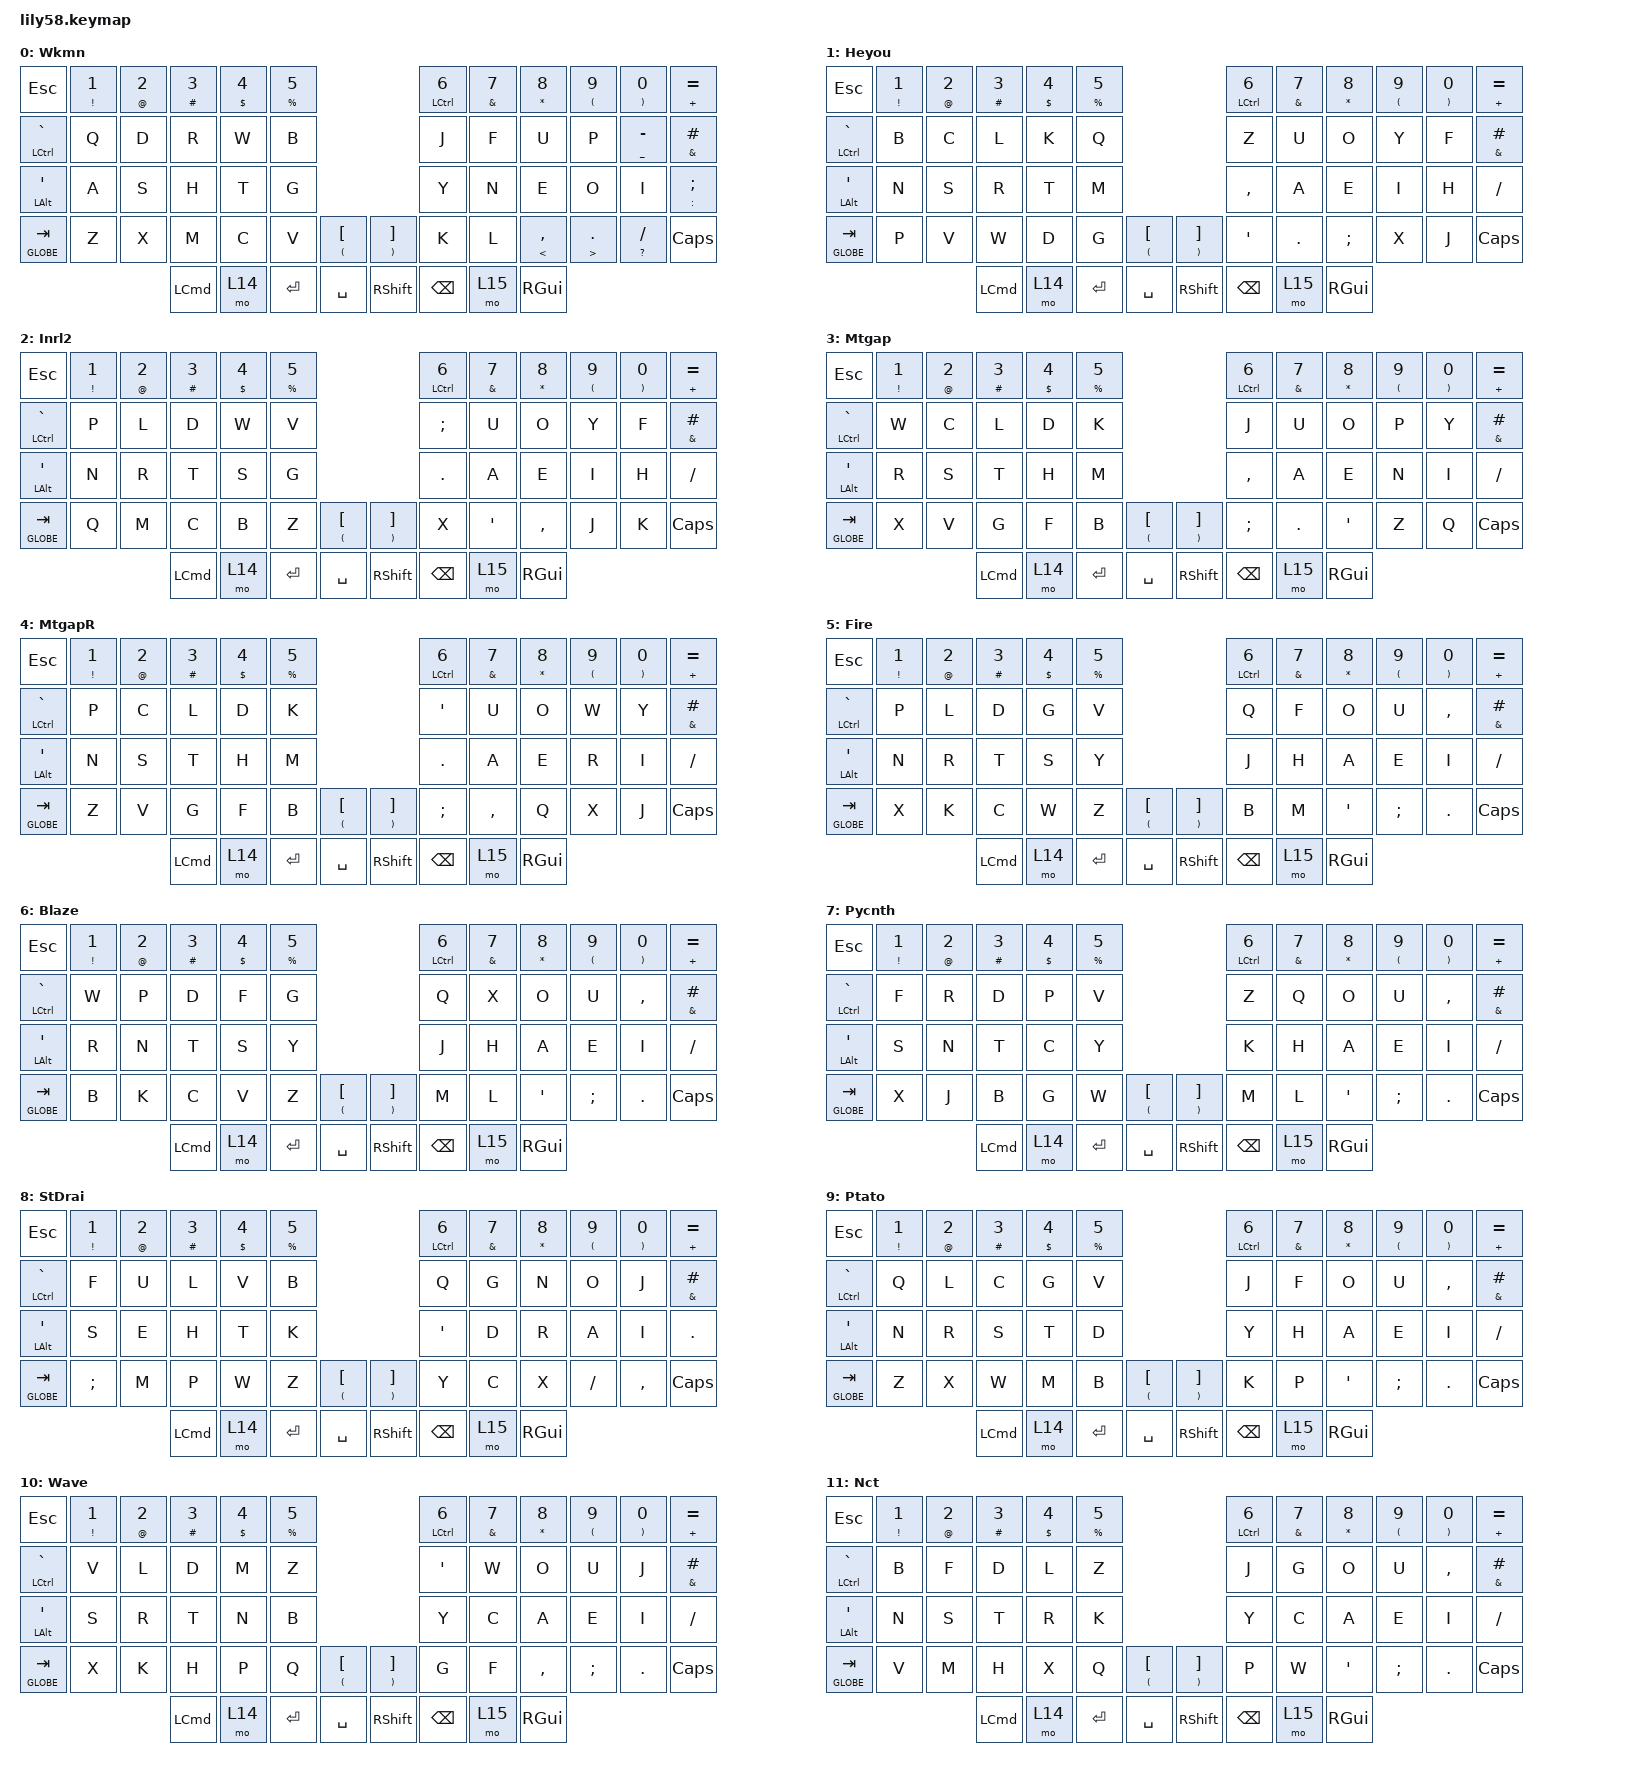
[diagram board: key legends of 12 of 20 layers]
/*
 * Copyright (c) 2020 The ZMK Contributors
 *
 * SPDX-License-Identifier: MIT
 */

#include <behaviors.dtsi>
#include <dt-bindings/zmk/keys.h>
#include <dt-bindings/zmk/pointing.h>

/ {
    combos { compatible = "zmk,combos"; };

    keymap {
        compatible = "zmk,keymap";

        Workman {
            // ------------------------------------------------------------------------------------------------------------
            // |  ESC  |  1  |  2  |  3   |  4   |  5   |                   |  6   |  7    |  8    |  9   |   0   |   `   |
            // |  TAB  |  Q  |  W  |  E   |  R   |  T   |                   |  Y   |  U    |  I    |  O   |   P   |   -   |
            // |  CTRL |  A  |  S  |  D   |  F   |  G   |                   |  H   |  J    |  K    |  L   |   ;   |   '   |
            // | SHIFT |  Z  |  X  |  C   |  V   |  B   |   "["  |  |  "]"  |  N   |  M    |  ,    |  .   |   /   | SHIFT |
            //                     | ALT  | GUI  | LOWER|  SPACE |  | ENTER | RAISE| BSPC  | GUI   |

            display-name = "Wkmn";
            bindings = <
&kp ESC                 &mt EXCLAMATION NUMBER_1  &mt AT_SIGN NUMBER_2  &mt HASH NUMBER_3  &mt DOLLAR NUMBER_4  &mt PERCENT NUMBER_5                                                                            &mt LCTRL NUMBER_6  &mt AMPERSAND NUMBER_7  &mt ASTERISK NUMBER_8  &mt LEFT_PARENTHESIS NUMBER_9  &mt RIGHT_PARENTHESIS NUMBER_0  &mt PLUS EQUAL
&mt LEFT_CONTROL GRAVE  &kp Q                     &kp D                 &kp R              &kp W                &kp B                                                                                           &kp J               &kp F                   &kp U                  &kp P                          &mt UNDERSCORE MINUS            &mt AMPERSAND HASH
&mt LEFT_ALT SQT        &kp A                     &kp S                 &kp H              &kp T                &kp G                                                                                           &kp Y               &kp N                   &kp E                  &kp O                          &kp I                           &mt COLON SEMICOLON
&mt GLOBE TAB           &kp Z                     &kp X                 &kp M              &kp C                &kp V                 &mt LEFT_PARENTHESIS LEFT_BRACKET    &mt RIGHT_PARENTHESIS RIGHT_BRACKET  &kp K               &kp L                   &mt LESS_THAN COMMA    &mt GREATER_THAN PERIOD        &mt QUESTION SLASH              &kp CAPS
                                                                        &kp LEFT_COMMAND   &mo 14               &kp RET               &kp SPACE                            &kp RIGHT_SHIFT                      &kp BACKSPACE       &mo 15                  &kp RGUI
            >;

            sensor-bindings = <&inc_dec_kp C_VOL_UP C_VOL_DN>;
        };

        Heyyou {
            display-name = "Heyou";
            bindings = <
&kp ESC                 &mt EXCLAMATION NUMBER_1  &mt AT_SIGN NUMBER_2  &mt HASH NUMBER_3  &mt DOLLAR NUMBER_4  &mt PERCENT NUMBER_5                                                                            &mt LCTRL NUMBER_6  &mt AMPERSAND NUMBER_7  &mt ASTERISK NUMBER_8  &mt LEFT_PARENTHESIS NUMBER_9  &mt RIGHT_PARENTHESIS NUMBER_0  &mt PLUS EQUAL
&mt LEFT_CONTROL GRAVE  &kp B                     &kp C                 &kp L              &kp K                &kp Q                                                                                           &kp Z               &kp U                   &kp O                  &kp Y                          &kp F                           &mt AMPERSAND HASH
&mt LEFT_ALT SQT        &kp N                     &kp S                 &kp R              &kp T                &kp M                                                                                           &kp COMMA           &kp A                   &kp E                  &kp I                          &kp H                           &kp FSLH
&mt GLOBE TAB           &kp P                     &kp V                 &kp W              &kp D                &kp G                 &mt LEFT_PARENTHESIS LEFT_BRACKET    &mt RIGHT_PARENTHESIS RIGHT_BRACKET  &kp SQT             &kp DOT                 &kp SEMI               &kp X                          &kp J                           &kp CAPS
                                                                        &kp LEFT_COMMAND   &mo 14               &kp RET               &kp SPACE                            &kp RIGHT_SHIFT                      &kp BACKSPACE       &mo 15                  &kp RGUI
            >;

            sensor-bindings = <&inc_dec_kp C_VOL_UP C_VOL_DN>;
        };

        Inrolly2 {
            display-name = "Inrl2";
            bindings = <
&kp ESC                 &mt EXCLAMATION NUMBER_1  &mt AT_SIGN NUMBER_2  &mt HASH NUMBER_3  &mt DOLLAR NUMBER_4  &mt PERCENT NUMBER_5                                                                            &mt LCTRL NUMBER_6  &mt AMPERSAND NUMBER_7  &mt ASTERISK NUMBER_8  &mt LEFT_PARENTHESIS NUMBER_9  &mt RIGHT_PARENTHESIS NUMBER_0  &mt PLUS EQUAL
&mt LEFT_CONTROL GRAVE  &kp P                     &kp L                 &kp D              &kp W                &kp V                                                                                           &kp SEMI            &kp U                   &kp O                  &kp Y                          &kp F                           &mt AMPERSAND HASH
&mt LEFT_ALT SQT        &kp N                     &kp R                 &kp T              &kp S                &kp G                                                                                           &kp DOT             &kp A                   &kp E                  &kp I                          &kp H                           &kp FSLH
&mt GLOBE TAB           &kp Q                     &kp M                 &kp C              &kp B                &kp Z                 &mt LEFT_PARENTHESIS LEFT_BRACKET    &mt RIGHT_PARENTHESIS RIGHT_BRACKET  &kp X               &kp SQT                 &kp COMMA              &kp J                          &kp K                           &kp CAPS
                                                                        &kp LEFT_COMMAND   &mo 14               &kp RET               &kp SPACE                            &kp RIGHT_SHIFT                      &kp BACKSPACE       &mo 15                  &kp RGUI
            >;

            sensor-bindings = <&inc_dec_kp C_VOL_UP C_VOL_DN>;
        };

        Mtgap {
            display-name = "Mtgap";
            bindings = <
&kp ESC                 &mt EXCLAMATION NUMBER_1  &mt AT_SIGN NUMBER_2  &mt HASH NUMBER_3  &mt DOLLAR NUMBER_4  &mt PERCENT NUMBER_5                                                                            &mt LCTRL NUMBER_6  &mt AMPERSAND NUMBER_7  &mt ASTERISK NUMBER_8  &mt LEFT_PARENTHESIS NUMBER_9  &mt RIGHT_PARENTHESIS NUMBER_0  &mt PLUS EQUAL
&mt LEFT_CONTROL GRAVE  &kp W                     &kp C                 &kp L              &kp D                &kp K                                                                                           &kp J               &kp U                   &kp O                  &kp P                          &kp Y                           &mt AMPERSAND HASH
&mt LEFT_ALT SQT        &kp R                     &kp S                 &kp T              &kp H                &kp M                                                                                           &kp COMMA           &kp A                   &kp E                  &kp N                          &kp I                           &kp FSLH
&mt GLOBE TAB           &kp X                     &kp V                 &kp G              &kp F                &kp B                 &mt LEFT_PARENTHESIS LEFT_BRACKET    &mt RIGHT_PARENTHESIS RIGHT_BRACKET  &kp SEMI            &kp DOT                 &kp SQT                &kp Z                          &kp Q                           &kp CAPS
                                                                        &kp LEFT_COMMAND   &mo 14               &kp RET               &kp SPACE                            &kp RIGHT_SHIFT                      &kp BACKSPACE       &mo 15                  &kp RGUI
            >;

            sensor-bindings = <&inc_dec_kp C_VOL_UP C_VOL_DN>;
        };

        MtgapR {
            display-name = "MtgapR";
            bindings = <
&kp ESC                 &mt EXCLAMATION NUMBER_1  &mt AT_SIGN NUMBER_2  &mt HASH NUMBER_3  &mt DOLLAR NUMBER_4  &mt PERCENT NUMBER_5                                                                            &mt LCTRL NUMBER_6  &mt AMPERSAND NUMBER_7  &mt ASTERISK NUMBER_8  &mt LEFT_PARENTHESIS NUMBER_9  &mt RIGHT_PARENTHESIS NUMBER_0  &mt PLUS EQUAL
&mt LEFT_CONTROL GRAVE  &kp P                     &kp C                 &kp L              &kp D                &kp K                                                                                           &kp SQT             &kp U                   &kp O                  &kp W                          &kp Y                           &mt AMPERSAND HASH
&mt LEFT_ALT SQT        &kp N                     &kp S                 &kp T              &kp H                &kp M                                                                                           &kp DOT             &kp A                   &kp E                  &kp R                          &kp I                           &kp FSLH
&mt GLOBE TAB           &kp Z                     &kp V                 &kp G              &kp F                &kp B                 &mt LEFT_PARENTHESIS LEFT_BRACKET    &mt RIGHT_PARENTHESIS RIGHT_BRACKET  &kp SEMI            &kp COMMA               &kp Q                  &kp X                          &kp J                           &kp CAPS
                                                                        &kp LEFT_COMMAND   &mo 14               &kp RET               &kp SPACE                            &kp RIGHT_SHIFT                      &kp BACKSPACE       &mo 15                  &kp RGUI
            >;

            sensor-bindings = <&inc_dec_kp C_VOL_UP C_VOL_DN>;
        };

        Fire {
            display-name = "Fire";
            bindings = <
&kp ESC                 &mt EXCLAMATION NUMBER_1  &mt AT_SIGN NUMBER_2  &mt HASH NUMBER_3  &mt DOLLAR NUMBER_4  &mt PERCENT NUMBER_5                                                                            &mt LCTRL NUMBER_6  &mt AMPERSAND NUMBER_7  &mt ASTERISK NUMBER_8  &mt LEFT_PARENTHESIS NUMBER_9  &mt RIGHT_PARENTHESIS NUMBER_0  &mt PLUS EQUAL
&mt LEFT_CONTROL GRAVE  &kp P                     &kp L                 &kp D              &kp G                &kp V                                                                                           &kp Q               &kp F                   &kp O                  &kp U                          &kp COMMA                       &mt AMPERSAND HASH
&mt LEFT_ALT SQT        &kp N                     &kp R                 &kp T              &kp S                &kp Y                                                                                           &kp J               &kp H                   &kp A                  &kp E                          &kp I                           &kp FSLH
&mt GLOBE TAB           &kp X                     &kp K                 &kp C              &kp W                &kp Z                 &mt LEFT_PARENTHESIS LEFT_BRACKET    &mt RIGHT_PARENTHESIS RIGHT_BRACKET  &kp B               &kp M                   &kp SQT                &kp SEMI                       &kp DOT                         &kp CAPS
                                                                        &kp LEFT_COMMAND   &mo 14               &kp RET               &kp SPACE                            &kp RIGHT_SHIFT                      &kp BACKSPACE       &mo 15                  &kp RGUI
            >;

            sensor-bindings = <&inc_dec_kp C_VOL_UP C_VOL_DN>;
        };

        Blaze {
            display-name = "Blaze";
            bindings = <
&kp ESC                 &mt EXCLAMATION NUMBER_1  &mt AT_SIGN NUMBER_2  &mt HASH NUMBER_3  &mt DOLLAR NUMBER_4  &mt PERCENT NUMBER_5                                                                            &mt LCTRL NUMBER_6  &mt AMPERSAND NUMBER_7  &mt ASTERISK NUMBER_8  &mt LEFT_PARENTHESIS NUMBER_9  &mt RIGHT_PARENTHESIS NUMBER_0  &mt PLUS EQUAL
&mt LEFT_CONTROL GRAVE  &kp W                     &kp P                 &kp D              &kp F                &kp G                                                                                           &kp Q               &kp X                   &kp O                  &kp U                          &kp COMMA                       &mt AMPERSAND HASH
&mt LEFT_ALT SQT        &kp R                     &kp N                 &kp T              &kp S                &kp Y                                                                                           &kp J               &kp H                   &kp A                  &kp E                          &kp I                           &kp FSLH
&mt GLOBE TAB           &kp B                     &kp K                 &kp C              &kp V                &kp Z                 &mt LEFT_PARENTHESIS LEFT_BRACKET    &mt RIGHT_PARENTHESIS RIGHT_BRACKET  &kp M               &kp L                   &kp SQT                &kp SEMI                       &kp DOT                         &kp CAPS
                                                                        &kp LEFT_COMMAND   &mo 14               &kp RET               &kp SPACE                            &kp RIGHT_SHIFT                      &kp BACKSPACE       &mo 15                  &kp RGUI
            >;

            sensor-bindings = <&inc_dec_kp C_VOL_UP C_VOL_DN>;
        };

        Pycantha {
            display-name = "Pycnth";
            bindings = <
&kp ESC                 &mt EXCLAMATION NUMBER_1  &mt AT_SIGN NUMBER_2  &mt HASH NUMBER_3  &mt DOLLAR NUMBER_4  &mt PERCENT NUMBER_5                                                                            &mt LCTRL NUMBER_6  &mt AMPERSAND NUMBER_7  &mt ASTERISK NUMBER_8  &mt LEFT_PARENTHESIS NUMBER_9  &mt RIGHT_PARENTHESIS NUMBER_0  &mt PLUS EQUAL
&mt LEFT_CONTROL GRAVE  &kp F                     &kp R                 &kp D              &kp P                &kp V                                                                                           &kp Z               &kp Q                   &kp O                  &kp U                          &kp COMMA                       &mt AMPERSAND HASH
&mt LEFT_ALT SQT        &kp S                     &kp N                 &kp T              &kp C                &kp Y                                                                                           &kp K               &kp H                   &kp A                  &kp E                          &kp I                           &kp FSLH
&mt GLOBE TAB           &kp X                     &kp J                 &kp B              &kp G                &kp W                 &mt LEFT_PARENTHESIS LEFT_BRACKET    &mt RIGHT_PARENTHESIS RIGHT_BRACKET  &kp M               &kp L                   &kp SQT                &kp SEMI                       &kp DOT                         &kp CAPS
                                                                        &kp LEFT_COMMAND   &mo 14               &kp RET               &kp SPACE                            &kp RIGHT_SHIFT                      &kp BACKSPACE       &mo 15                  &kp RGUI
            >;

            sensor-bindings = <&inc_dec_kp C_VOL_UP C_VOL_DN>;
        };

        SehtDrai {
            display-name = "StDrai";
            bindings = <
&kp ESC                 &mt EXCLAMATION NUMBER_1  &mt AT_SIGN NUMBER_2  &mt HASH NUMBER_3  &mt DOLLAR NUMBER_4  &mt PERCENT NUMBER_5                                                                            &mt LCTRL NUMBER_6  &mt AMPERSAND NUMBER_7  &mt ASTERISK NUMBER_8  &mt LEFT_PARENTHESIS NUMBER_9  &mt RIGHT_PARENTHESIS NUMBER_0  &mt PLUS EQUAL
&mt LEFT_CONTROL GRAVE  &kp F                     &kp U                 &kp L              &kp V                &kp B                                                                                           &kp Q               &kp G                   &kp N                  &kp O                          &kp J                           &mt AMPERSAND HASH
&mt LEFT_ALT SQT        &kp S                     &kp E                 &kp H              &kp T                &kp K                                                                                           &kp SQT             &kp D                   &kp R                  &kp A                          &kp I                           &kp DOT
&mt GLOBE TAB           &kp SEMI                  &kp M                 &kp P              &kp W                &kp Z                 &mt LEFT_PARENTHESIS LEFT_BRACKET    &mt RIGHT_PARENTHESIS RIGHT_BRACKET  &kp Y               &kp C                   &kp X                  &kp FSLH                       &kp COMMA                       &kp CAPS
                                                                        &kp LEFT_COMMAND   &mo 14               &kp RET               &kp SPACE                            &kp RIGHT_SHIFT                      &kp BACKSPACE       &mo 15                  &kp RGUI
            >;

            sensor-bindings = <&inc_dec_kp C_VOL_UP C_VOL_DN>;
        };

        Potato {
            display-name = "Ptato";
            bindings = <
&kp ESC                 &mt EXCLAMATION NUMBER_1  &mt AT_SIGN NUMBER_2  &mt HASH NUMBER_3  &mt DOLLAR NUMBER_4  &mt PERCENT NUMBER_5                                                                            &mt LCTRL NUMBER_6  &mt AMPERSAND NUMBER_7  &mt ASTERISK NUMBER_8  &mt LEFT_PARENTHESIS NUMBER_9  &mt RIGHT_PARENTHESIS NUMBER_0  &mt PLUS EQUAL
&mt LEFT_CONTROL GRAVE  &kp Q                     &kp L                 &kp C              &kp G                &kp V                                                                                           &kp J               &kp F                   &kp O                  &kp U                          &kp COMMA                       &mt AMPERSAND HASH
&mt LEFT_ALT SQT        &kp N                     &kp R                 &kp S              &kp T                &kp D                                                                                           &kp Y               &kp H                   &kp A                  &kp E                          &kp I                           &kp FSLH
&mt GLOBE TAB           &kp Z                     &kp X                 &kp W              &kp M                &kp B                 &mt LEFT_PARENTHESIS LEFT_BRACKET    &mt RIGHT_PARENTHESIS RIGHT_BRACKET  &kp K               &kp P                   &kp SQT                &kp SEMI                       &kp DOT                         &kp CAPS
                                                                        &kp LEFT_COMMAND   &mo 14               &kp RET               &kp SPACE                            &kp RIGHT_SHIFT                      &kp BACKSPACE       &mo 15                  &kp RGUI
            >;

            sensor-bindings = <&inc_dec_kp C_VOL_UP C_VOL_DN>;
        };

        Wave {
            display-name = "Wave";
            bindings = <
&kp ESC                 &mt EXCLAMATION NUMBER_1  &mt AT_SIGN NUMBER_2  &mt HASH NUMBER_3  &mt DOLLAR NUMBER_4  &mt PERCENT NUMBER_5                                                                            &mt LCTRL NUMBER_6  &mt AMPERSAND NUMBER_7  &mt ASTERISK NUMBER_8  &mt LEFT_PARENTHESIS NUMBER_9  &mt RIGHT_PARENTHESIS NUMBER_0  &mt PLUS EQUAL
&mt LEFT_CONTROL GRAVE  &kp V                     &kp L                 &kp D              &kp M                &kp Z                                                                                           &kp SQT             &kp W                   &kp O                  &kp U                          &kp J                           &mt AMPERSAND HASH
&mt LEFT_ALT SQT        &kp S                     &kp R                 &kp T              &kp N                &kp B                                                                                           &kp Y               &kp C                   &kp A                  &kp E                          &kp I                           &kp FSLH
&mt GLOBE TAB           &kp X                     &kp K                 &kp H              &kp P                &kp Q                 &mt LEFT_PARENTHESIS LEFT_BRACKET    &mt RIGHT_PARENTHESIS RIGHT_BRACKET  &kp G               &kp F                   &kp COMMA              &kp SEMI                       &kp DOT                         &kp CAPS
                                                                        &kp LEFT_COMMAND   &mo 14               &kp RET               &kp SPACE                            &kp RIGHT_SHIFT                      &kp BACKSPACE       &mo 15                  &kp RGUI
            >;

            sensor-bindings = <&inc_dec_kp C_VOL_UP C_VOL_DN>;
        };

        Noctum {
            display-name = "Nct";
            bindings = <
&kp ESC                 &mt EXCLAMATION NUMBER_1  &mt AT_SIGN NUMBER_2  &mt HASH NUMBER_3  &mt DOLLAR NUMBER_4  &mt PERCENT NUMBER_5                                                                            &mt LCTRL NUMBER_6  &mt AMPERSAND NUMBER_7  &mt ASTERISK NUMBER_8  &mt LEFT_PARENTHESIS NUMBER_9  &mt RIGHT_PARENTHESIS NUMBER_0  &mt PLUS EQUAL
&mt LEFT_CONTROL GRAVE  &kp B                     &kp F                 &kp D              &kp L                &kp Z                                                                                           &kp J               &kp G                   &kp O                  &kp U                          &kp COMMA                       &mt AMPERSAND HASH
&mt LEFT_ALT SQT        &kp N                     &kp S                 &kp T              &kp R                &kp K                                                                                           &kp Y               &kp C                   &kp A                  &kp E                          &kp I                           &kp FSLH
&mt GLOBE TAB           &kp V                     &kp M                 &kp H              &kp X                &kp Q                 &mt LEFT_PARENTHESIS LEFT_BRACKET    &mt RIGHT_PARENTHESIS RIGHT_BRACKET  &kp P               &kp W                   &kp SQT                &kp SEMI                       &kp DOT                         &kp CAPS
                                                                        &kp LEFT_COMMAND   &mo 14               &kp RET               &kp SPACE                            &kp RIGHT_SHIFT                      &kp BACKSPACE       &mo 15                  &kp RGUI
            >;

            sensor-bindings = <&inc_dec_kp C_VOL_UP C_VOL_DN>;
        };

        Workman_1Hand {
            display-name = "Wkmn1";
            bindings = <
&mt PLUS EQUAL       &mt RIGHT_PARENTHESIS N0  &mt LEFT_PARENTHESIS N9  &mt ASTERISK N8      &mt AMPERSAND N7  &mt CARET NUMBER_6                                                                            &mt LCTRL NUMBER_6  &mt AMPERSAND NUMBER_7  &mt ASTERISK NUMBER_8  &mt LEFT_PARENTHESIS NUMBER_9  &mt RIGHT_PARENTHESIS NUMBER_0  &mt PLUS EQUAL
&mt AMPERSAND HASH   &mt UNDERSCORE MINUS      &kp P                    &kp U                &kp F             &kp J                                                                                         &kp J               &kp F                   &kp U                  &kp P                          &mt UNDERSCORE MINUS            &mt AMPERSAND HASH
&kp SPACE            &kp I                     &kp O                    &kp E                &kp N             &kp Y                                                                                         &kp Y               &kp N                   &kp E                  &kp O                          &kp I                           &kp SPACE
&mt COLON SEMICOLON  &mt QUESTION SLASH        &mt GREATER_THAN PERIOD  &mt LESS_THAN COMMA  &kp L             &kp K               &mt LEFT_PARENTHESIS LEFT_BRACKET    &mt RIGHT_PARENTHESIS RIGHT_BRACKET  &kp K               &kp L                   &mt LESS_THAN COMMA    &mt GREATER_THAN PERIOD        &mt QUESTION SLASH              &mt COLON SEMICOLON
                                                                        &kp RET              &kp BACKSPACE     &sk SPACE           &lt 13 SPACE                         &lt 13 SPACE                         &sk SPACE           &kp BACKSPACE           &kp RETURN
            >;

            sensor-bindings = <&inc_dec_kp C_VOL_UP C_VOL_DN>;
        };

        Workman_1.1Hand {
            display-name = "Wkmn2";
            bindings = <
&mt ESC TAB           &mt EXCLAMATION NUMBER_1  &mt AT_SIGN NUMBER_2  &mt HASH NUMBER_3  &mt DOLLAR NUMBER_4  &mt PERCENT NUMBER_5                                                                        &mt PERCENT N5     &mt DOLLAR NUMBER_4  &mt HASH NUMBER_3  &mt AT_SIGN NUMBER_2  &mt EXCLAMATION NUMBER_1  &mt ESC TAB
&mt AT_SIGN ASTERISK  &kp Q                     &kp D                 &kp R              &kp W                &kp B                                                                                       &kp B              &kp W                &kp R              &kp D                 &kp Q                     &mt AT_SIGN ASTERISK
&kp SPACE             &kp A                     &kp S                 &kp H              &kp T                &kp G                                                                                       &kp G              &kp T                &kp H              &kp S                 &kp A                     &kp SPACE
&sk LEFT_SHIFT        &kp Z                     &kp X                 &kp M              &kp C                &kp V                 &mt LEFT_BRACE LEFT_PARENTHESIS    &mt RIGHT_BRACE RIGHT_PARENTHESIS  &kp V              &kp C                &kp M              &kp X                 &kp Z                     &sk RIGHT_SHIFT
                                                                      &sk LEFT_ALT       &sk LEFT_CONTROL     &sk LEFT_COMMAND      &trans                             &trans                             &sk RIGHT_COMMAND  &sk RIGHT_CONTROL    &sk RIGHT_ALT
            >;

            sensor-bindings = <&inc_dec_kp C_VOL_UP C_VOL_DN>;
        };

        symbols {
            bindings = <
&kp ESCAPE              &kp F1          &kp F2                &kp F3            &kp F4        &kp F5                                                             &kp F6            &kp F7             &kp F8             &kp F9                 &kp F10          &tog 15
&kp GRAVE               &kp LEFT_BRACE  &kp ASTERISK          &kp PERCENT       &kp SLASH     &kp PLUS                                                           &kp AMPERSAND     &kp QUESTION       &kp COLON          &kp UNDERSCORE         &kp RIGHT_BRACE  &mt NON_US_BACKSLASH PIPE
&mt LEFT_CONTROL TILDE  &kp SEMICOLON   &kp LEFT_PARENTHESIS  &kp EQUAL         &kp COMMA     &kp LESS_THAN                                                      &kp GREATER_THAN  &kp PERIOD         &kp DOUBLE_QUOTES  &kp RIGHT_PARENTHESIS  &kp MINUS        &kp HASH
&kp TAB                 &mt DOLLAR N1   &kp N2                &kp N3            &mt HASH N4   &mt EXCLAMATION N5  &kp LEFT_PARENTHESIS    &kp RIGHT_PARENTHESIS  &kp N6            &kp N7             &kp N8             &kp N9                 &kp N0           &kp CAPSLOCK
                                                              &kp LEFT_COMMAND  &kp LEFT_ALT  &trans              &kp SPACE               &kp RIGHT_SHIFT        &kp BACKSPACE     &mt RIGHT_ALT RET  &kp RIGHT_COMMAND
            >;

            label = "Symb";
        };

        system {
            bindings = <
&tog 0     &tog 1          &tog 2          &tog 3            &tog 4        &tog 5                                        &kp C_PREV     &kp C_PLAY_PAUSE  &kp C_NEXT         &none               &kp C_BRIGHTNESS_DEC  &kp C_BRIGHTNESS_INC
&tog 6     &tog 7          &tog 8          &tog 9            &tog 10       &tog 11                                       &mt HOME N7    &mt PIPE N8       &mt PAGE_UP N9     &mt MINUS PLUS      &kp LEFT_PARENTHESIS  &kp RIGHT_PARENTHESIS
&tog 12    &none           &mmv MOVE_UP    &none             &msc SCRL_UP  &msc SCRL_DOWN                                &mt KP_NUM N4  &mt PERCENT N5    &mt CARET N6       &mt SLASH ASTERISK  &kp UP_ARROW          &none
&mkp MCLK  &mmv MOVE_LEFT  &mmv MOVE_DOWN  &mmv MOVE_RIGHT   &mkp LCLK     &mkp RCLK       &none        &mt INS N0       &mt END N1     &kp N2            &mt PAGE_DOWN N3   &kp LEFT_ARROW      &kp DOWN_ARROW        &kp RIGHT_ARROW
                                           &kp LEFT_COMMAND  &trans        &mkp RCLK       &mkp LCLK    &kp RIGHT_SHIFT  &kp BACKSPACE  &kp RET           &kp RIGHT_COMMAND
            >;

            label = "Sys";
        };

        x1.en.ergodox_symbols {
            bindings = <
&kp ESCAPE     &mt EXCLAMATION NUMBER_1  &mt AT_SIGN NUMBER_2    &mt HASH NUMBER_3   &mt DOLLAR NUMBER_4  &mt PERCENT N5                                                                               &mt LCTRL NUMBER_6       &mt AMPERSAND N7            &mt ASTERISK N8       &mt LEFT_PARENTHESIS N9  &mt RIGHT_PARENTHESIS N0  &mt PLUS EQUAL
&mt GRAVE Z    &mt LEFT_BRACKET Q        &mt ASTERISK P          &mt PERCENT L       &mt K C              &mt PLUS F                                                                                   &mt AMPERSAND SQT        &mt QUESTION DOUBLE_QUOTES  &mt COLON O           &mt UNDERSCORE Y         &mt RIGHT_BRACKET K       &mt BACKSLASH PIPE
&mt TILDE V    &mt SEMICOLON R           &mt LEFT_PARENTHESIS N  &mt EQUAL F         &mt COMMA S          &mt LESS_THAN D                                                                              &mt Q U                  &mt PERIOD A                &mt DOUBLE_QUOTES E   &mt RIGHT_PARENTHESIS I  &mt MINUS H               &kp RIGHT_CONTROL
&mt GLOBE TAB  &mt DOLLAR X              &mt LESS_THAN B         &mt GREATER_THAN M  &mt HASH G           &mt EXCLAMATION W  &mt LEFT_PARENTHESIS LEFT_BRACKET    &mt RIGHT_PARENTHESIS RIGHT_BRACKET  &mt DOUBLE_QUOTES COMMA  &mt SQT PERIOD              &mt UNDERSCORE MINUS  &kp SLASH                &kp J                     &kp CAPS
                                                                 &kp LEFT_COMMAND    &mo 15               &mo 14             &kp SPACE                            &kp RSHFT                            &kp BSPC                 &mt RIGHT_ALT RET           &kp RIGHT_COMMAND
            >;
        };

        x1.en.ergodox {
            bindings = <
&kp ESCAPE     &mt EXCLAMATION NUMBER_1  &mt AT_SIGN NUMBER_2  &mt HASH NUMBER_3  &mt DOLLAR NUMBER_4  &mt PERCENT N5                                                                            &mt LCTRL NUMBER_6       &mt AMPERSAND N7            &mt ASTERISK N8       &mt LEFT_PARENTHESIS N9  &mt RIGHT_PARENTHESIS N0  &mt PLUS EQUAL
&kp Z          &kp Q                     &kp P                 &kp L              &kp C                &kp F                                                                                     &mt AMPERSAND SQT        &mt QUESTION DOUBLE_QUOTES  &kp O                 &kp Y                    &kp K                     &mt BACKSLASH PIPE
&kp V          &kp R                     &kp N                 &kp T              &kp S                &kp D                                                                                     &kp U                    &kp A                       &kp E                 &kp I                    &kp H                     &kp RIGHT_CONTROL
&mt GLOBE TAB  &kp X                     &kp B                 &kp M              &kp G                &kp W           &mt LEFT_PARENTHESIS LEFT_BRACKET    &mt RIGHT_PARENTHESIS RIGHT_BRACKET  &mt DOUBLE_QUOTES COMMA  &mt SQT PERIOD              &mt UNDERSCORE MINUS  &kp SLASH                &kp J                     &kp CAPS
                                                               &kp LEFT_COMMAND   &mo 15               &mo 14          &kp SPACE                            &kp RSHFT                            &kp BSPC                 &mt RIGHT_ALT RET           &kp RIGHT_COMMAND
            >;

            label = "X1";
        };

        hs-indeks.en.ergodox {
            display-name = "Indks";
            bindings = <
&kp ESC        &mt EXCLAMATION NUMBER_1  &mt AT_SIGN NUMBER_2  &mt HASH NUMBER_3  &mt DOLLAR NUMBER_4  &mt PERCENT NUMBER_5                                                                            &mt LCTRL NUMBER_6  &mt AMPERSAND NUMBER_7  &mt ASTERISK NUMBER_8  &mt LEFT_PARENTHESIS NUMBER_9  &mt RIGHT_PARENTHESIS NUMBER_0  &mt PLUS EQUAL
&kp J          &kp Q                     &kp P                 &kp L              &kp C                &kp G                                                                                           &kp DOUBLE_QUOTES   &kp U                   &kp O                  &mt UNDERSCORE MINUS           &mt COLON SEMICOLON             &mt BACKSLASH PIPE
&kp Z          &kp R                     &kp N                 &kp T              &kp S                &kp F                                                                                           &kp Y               &kp H                   &kp E                  &kp I                          &kp A                           &kp RIGHT_CONTROL
&mt GLOBE TAB  &kp X                     &kp B                 &kp M              &kp D                &kp W                 &mt LEFT_PARENTHESIS LEFT_BRACKET    &mt RIGHT_PARENTHESIS RIGHT_BRACKET  &kp SQT             &kp K                   &mt LESS_THAN COMMA    &mt GREATER_THAN COMMA         &mt QUESTION SLASH              &kp CAPS
                                                               &kp LEFT_COMMAND   &mo 15               &mo 14                &kp SPACE                            &kp RIGHT_SHIFT                      &kp BACKSPACE       &mt RIGHT_ALT RET       &kp RGUI
            >;

            sensor-bindings = <&inc_dec_kp C_VOL_UP C_VOL_DN>;
            label = "Indeks";
        };

        DvorakLH {
            bindings = <
&trans  &trans  &trans  &trans  &trans  &trans                    &trans  &trans  &trans  &kp Q  &kp X  &kp Z
&trans  &trans  &trans  &trans  &trans  &trans                    &kp Y   &kp S   &kp R   &kp U  &kp O  &kp B
&trans  &trans  &trans  &trans  &trans  &trans                    &kp A   &kp E   &kp H   &kp T  &kp D  &kp C
&trans  &trans  &trans  &trans  &trans  &trans  &trans    &trans  &kp I   &kp N   &kp K   &kp G  &kp W  &kp V
                        &trans  &trans  &trans  &trans    &trans  &trans  &trans  &trans
            >;
        };
    };
};
